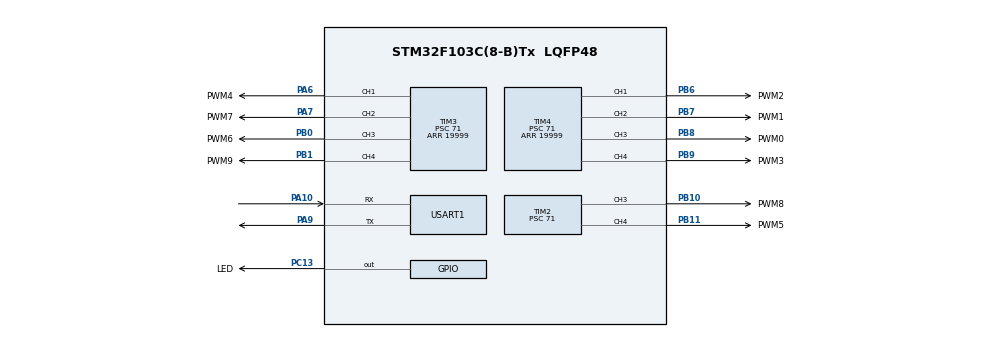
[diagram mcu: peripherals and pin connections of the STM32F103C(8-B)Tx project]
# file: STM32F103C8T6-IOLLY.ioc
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Dma.Request0=USART1_RX
Dma.Request1=USART1_TX
Dma.USART1_RX.0.Direction=DMA_PERIPH_TO_MEMORY
Dma.USART1_RX.0.Instance=DMA1_Channel5
Dma.USART1_RX.0.MemDataAlignment=DMA_MDATAALIGN_BYTE
Dma.USART1_RX.0.MemInc=DMA_MINC_ENABLE
Dma.USART1_RX.0.Mode=DMA_NORMAL
Dma.USART1_RX.0.PeriphDataAlignment=DMA_PDATAALIGN_BYTE
Dma.USART1_RX.0.PeriphInc=DMA_PINC_DISABLE
Dma.USART1_RX.0.Priority=DMA_PRIORITY_LOW
Dma.USART1_TX.1.Direction=DMA_MEMORY_TO_PERIPH
Dma.USART1_TX.1.Instance=DMA1_Channel4
Dma.USART1_TX.1.MemDataAlignment=DMA_MDATAALIGN_BYTE
Dma.USART1_TX.1.MemInc=DMA_MINC_ENABLE
Dma.USART1_TX.1.Mode=DMA_NORMAL
Dma.USART1_TX.1.PeriphDataAlignment=DMA_PDATAALIGN_BYTE
Dma.USART1_TX.1.PeriphInc=DMA_PINC_DISABLE
Dma.USART1_TX.1.Priority=DMA_PRIORITY_LOW
FREERTOS.Tasks01=defaultTask,24,128,StartDefaultTask,Default,NULL,Dynamic,NULL,NULL;RobotTask,16,128,StartRobotTask,Default,NULL,Dynamic,NULL,NULL
Mcu.Family=STM32F1
Mcu.Name=STM32F103C(8-B)Tx
Mcu.Package=LQFP48
NVIC.DMA1_Channel4_IRQn=true\:5\:0\:false\:false\:true\:true\:false\:true\:true
NVIC.DMA1_Channel5_IRQn=true\:5\:0\:false\:false\:true\:true\:false\:true\:true
NVIC.PriorityGroup=NVIC_PRIORITYGROUP_4
NVIC.TIM1_UP_IRQn=true\:15\:0\:false\:false\:true\:false\:false\:true\:true
NVIC.TimeBase=TIM1_UP_IRQn
NVIC.TimeBaseIP=TIM1
PA10.Mode=Asynchronous
PA10.Signal=USART1_RX
PA13.Mode=Serial_Wire
PA13.Signal=SYS_JTMS-SWDIO
PA14.Mode=Serial_Wire
PA14.Signal=SYS_JTCK-SWCLK
PA6.GPIO_Label=PWM4
PA6.Signal=S_TIM3_CH1
PA7.GPIO_Label=PWM7
PA7.Signal=S_TIM3_CH2
PA9.Mode=Asynchronous
PA9.Signal=USART1_TX
PB0.GPIO_Label=PWM6
PB0.Signal=S_TIM3_CH3
PB1.GPIO_Label=PWM9
PB1.Signal=S_TIM3_CH4
PB10.GPIO_Label=PWM8
PB10.Signal=S_TIM2_CH3
PB11.GPIO_Label=PWM5
PB11.Signal=S_TIM2_CH4
PB6.GPIO_Label=PWM2
PB6.Signal=S_TIM4_CH1
PB7.GPIO_Label=PWM1
PB7.Signal=S_TIM4_CH2
PB8.GPIO_Label=PWM0
PB8.Signal=S_TIM4_CH3
PB9.GPIO_Label=PWM3
PB9.Signal=S_TIM4_CH4
PC13-TAMPER-RTC.GPIO_Label=LED
PC13-TAMPER-RTC.Signal=GPIO_Output
PC14-OSC32_IN.Mode=LSE-External-Oscillator
PC14-OSC32_IN.Signal=RCC_OSC32_IN
PC15-OSC32_OUT.Mode=LSE-External-Oscillator
PC15-OSC32_OUT.Signal=RCC_OSC32_OUT
PD0-OSC_IN.Mode=HSE-External-Oscillator
PD0-OSC_IN.Signal=RCC_OSC_IN
PD1-OSC_OUT.Mode=HSE-External-Oscillator
PD1-OSC_OUT.Signal=RCC_OSC_OUT
ProjectManager.HeapSize=0x200
ProjectManager.StackSize=0x400
ProjectManager.TargetToolchain=CMake
RCC.AHBFreq_Value=72000000
RCC.APB1CLKDivider=RCC_HCLK_DIV2
RCC.APB1Freq_Value=36000000
RCC.APB1TimFreq_Value=72000000
RCC.APB2Freq_Value=72000000
RCC.APB2TimFreq_Value=72000000
RCC.HCLKFreq_Value=72000000
RCC.PLLMUL=RCC_PLL_MUL9
RCC.PLLSourceVirtual=RCC_PLLSOURCE_HSE
RCC.SYSCLKFreq_VALUE=72000000
RCC.SYSCLKSource=RCC_SYSCLKSOURCE_PLLCLK
RCC.USBFreq_Value=72000000
SH.S_TIM2_CH3.0=TIM2_CH3,PWM Generation3 CH3
SH.S_TIM2_CH4.0=TIM2_CH4,PWM Generation4 CH4
SH.S_TIM3_CH1.0=TIM3_CH1,PWM Generation1 CH1
SH.S_TIM3_CH2.0=TIM3_CH2,PWM Generation2 CH2
SH.S_TIM3_CH3.0=TIM3_CH3,PWM Generation3 CH3
SH.S_TIM3_CH4.0=TIM3_CH4,PWM Generation4 CH4
SH.S_TIM4_CH1.0=TIM4_CH1,PWM Generation1 CH1
SH.S_TIM4_CH2.0=TIM4_CH2,PWM Generation2 CH2
SH.S_TIM4_CH3.0=TIM4_CH3,PWM Generation3 CH3
SH.S_TIM4_CH4.0=TIM4_CH4,PWM Generation4 CH4
TIM2.Channel-PWM\ Generation3\ CH3=TIM_CHANNEL_3
TIM2.Channel-PWM\ Generation4\ CH4=TIM_CHANNEL_4
TIM2.Period=19999
TIM2.Prescaler=71
TIM2.Pulse-PWM\ Generation3\ CH3=0
TIM2.Pulse-PWM\ Generation4\ CH4=0
TIM3.AutoReloadPreload=TIM_AUTORELOAD_PRELOAD_ENABLE
TIM3.Channel-PWM\ Generation1\ CH1=TIM_CHANNEL_1
TIM3.Channel-PWM\ Generation2\ CH2=TIM_CHANNEL_2
TIM3.Channel-PWM\ Generation3\ CH3=TIM_CHANNEL_3
TIM3.Channel-PWM\ Generation4\ CH4=TIM_CHANNEL_4
TIM3.Period=19999
TIM3.Prescaler=71
TIM3.Pulse-PWM\ Generation1\ CH1=0
TIM3.Pulse-PWM\ Generation2\ CH2=0
TIM3.Pulse-PWM\ Generation3\ CH3=0
TIM3.Pulse-PWM\ Generation4\ CH4=0
TIM4.AutoReloadPreload=TIM_AUTORELOAD_PRELOAD_ENABLE
TIM4.Channel-PWM\ Generation1\ CH1=TIM_CHANNEL_1
TIM4.Channel-PWM\ Generation2\ CH2=TIM_CHANNEL_2
TIM4.Channel-PWM\ Generation3\ CH3=TIM_CHANNEL_3
TIM4.Channel-PWM\ Generation4\ CH4=TIM_CHANNEL_4
TIM4.Period=19999
TIM4.Prescaler=71
TIM4.Pulse-PWM\ Generation1\ CH1=0
TIM4.Pulse-PWM\ Generation2\ CH2=0
TIM4.Pulse-PWM\ Generation3\ CH3=0
TIM4.Pulse-PWM\ Generation4\ CH4=0
USART1.VirtualMode=VM_ASYNC
VP_FREERTOS_VS_CMSIS_V2.Mode=CMSIS_V2
VP_SYS_VS_tim1.Mode=TIM1
board=custom

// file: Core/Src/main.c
/* USER CODE BEGIN Header */
/**
  ******************************************************************************
  * @file           : main.c
  * @brief          : Main program body
  ******************************************************************************
  * @attention
  *
  * Copyright (c) 2026 STMicroelectronics.
  * All rights reserved.
  *
  * This software is licensed under terms that can be found in the LICENSE file
  * in the root directory of this software component.
  * If no LICENSE file comes with this software, it is provided AS-IS.
  *
  ******************************************************************************
  */
/* USER CODE END Header */
#include "main.h"
#include "cmsis_os.h"
#include "dma.h"
#include "tim.h"
#include "usart.h"
#include "gpio.h"

void SystemClock_Config(void);
void MX_FREERTOS_Init(void);

int main(void)
{

  /* MCU Configuration--------------------------------------------------------*/

  /* Reset of all peripherals, Initializes the Flash interface and the Systick. */
  HAL_Init();

  /* Configure the system clock */
  SystemClock_Config();

  /* Initialize all configured peripherals */
  MX_GPIO_Init();
  MX_DMA_Init();
  MX_TIM2_Init();
  MX_TIM3_Init();
  MX_TIM4_Init();
  MX_USART1_UART_Init();

  /* Init scheduler */
  osKernelInitialize();  /* Call init function for freertos objects (in cmsis_os2.c) */
  MX_FREERTOS_Init();

  /* Start scheduler */
  osKernelStart();

  /* We should never get here as control is now taken by the scheduler */

  /* Infinite loop */
  while (1)
  {

  }
}

void SystemClock_Config(void)
{
  LL_FLASH_SetLatency(LL_FLASH_LATENCY_2);
  while(LL_FLASH_GetLatency()!= LL_FLASH_LATENCY_2)
  {
  }
  LL_RCC_HSE_Enable();

   /* Wait till HSE is ready */
  while(LL_RCC_HSE_IsReady() != 1)
  {

  }
  LL_RCC_PLL_ConfigDomain_SYS(LL_RCC_PLLSOURCE_HSE_DIV_1, LL_RCC_PLL_MUL_9);
  LL_RCC_PLL_Enable();

   /* Wait till PLL is ready */
  while(LL_RCC_PLL_IsReady() != 1)
  {

  }
  LL_RCC_SetAHBPrescaler(LL_RCC_SYSCLK_DIV_1);
  LL_RCC_SetAPB1Prescaler(LL_RCC_APB1_DIV_2);
  LL_RCC_SetAPB2Prescaler(LL_RCC_APB2_DIV_1);
  LL_RCC_SetSysClkSource(LL_RCC_SYS_CLKSOURCE_PLL);

   /* Wait till System clock is ready */
  while(LL_RCC_GetSysClkSource() != LL_RCC_SYS_CLKSOURCE_STATUS_PLL)
  {

  }
  LL_SetSystemCoreClock(72000000);

   /* Update the time base */
  if (HAL_InitTick (TICK_INT_PRIORITY) != HAL_OK)
  {
    Error_Handler();
  }
}

void HAL_TIM_PeriodElapsedCallback(TIM_HandleTypeDef *htim)
{
  if (htim->Instance == TIM1)
  {
    HAL_IncTick();
  }
}

void Error_Handler(void)
{
  __disable_irq();
  while (1)
  {
  }
}

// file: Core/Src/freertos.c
/* USER CODE BEGIN Header */
/**
  ******************************************************************************
  * File Name          : freertos.c
  * Description        : Code for freertos applications
  ******************************************************************************
  * @attention
  *
  * Copyright (c) 2026 STMicroelectronics.
  * All rights reserved.
  *
  * This software is licensed under terms that can be found in the LICENSE file
  * in the root directory of this software component.
  * If no LICENSE file comes with this software, it is provided AS-IS.
  *
  ******************************************************************************
  */
/* USER CODE END Header */

#include "FreeRTOS.h"
#include "task.h"
#include "main.h"
#include "cmsis_os.h"

/* USER CODE BEGIN Includes */
#include "minikame.h"
/* USER CODE END Includes */

/* USER CODE BEGIN Variables */
MiniKame_t robot;
/* USER CODE END Variables */
/* Definitions for defaultTask */
osThreadId_t defaultTaskHandle;
const osThreadAttr_t defaultTask_attributes = {
  .name = "defaultTask",
  .stack_size = 128 * 4,
  .priority = (osPriority_t) osPriorityNormal,
};
/* Definitions for RobotTask */
osThreadId_t RobotTaskHandle;
const osThreadAttr_t RobotTask_attributes = {
  .name = "RobotTask",
  .stack_size = 128 * 4,
  .priority = (osPriority_t) osPriorityBelowNormal,
};

void StartDefaultTask(void *argument);
void StartRobotTask(void *argument);

void MX_FREERTOS_Init(void); /* (MISRA C 2004 rule 8.1) */

void MX_FREERTOS_Init(void) {

  /* Create the thread(s) */
  /* creation of defaultTask */
  defaultTaskHandle = osThreadNew(StartDefaultTask, NULL, &defaultTask_attributes);

  /* creation of RobotTask */
  RobotTaskHandle = osThreadNew(StartRobotTask, NULL, &RobotTask_attributes);

}

void StartDefaultTask(void *argument)
{
  for(;;)
  {
    osDelay(1);
  }
}

void StartRobotTask(void *argument)
{
  /* USER CODE BEGIN StartRobotTask */
  MiniKame_Init(&robot);
  osDelay(1000);
  MiniKame_Walk(&robot, 5, 1000);
  /* Infinite loop */
  for(;;)
  {
    LL_GPIO_TogglePin(LED_GPIO_Port, LED_Pin);
    osDelay(1000);
    LL_GPIO_TogglePin(LED_GPIO_Port, LED_Pin);
    osDelay(1000);
  }
  /* USER CODE END StartRobotTask */
}
